VERSION ""

NS_ :

BS_:

BU_: EON PCM XXX EPS VSA

BO_ 356 HEADLIGHT_STATUS: 8 PCM
 SG_ LOW_BEAM_STATUS : 1|1@1+ (1,0) [0|1] "" Vector__XXX

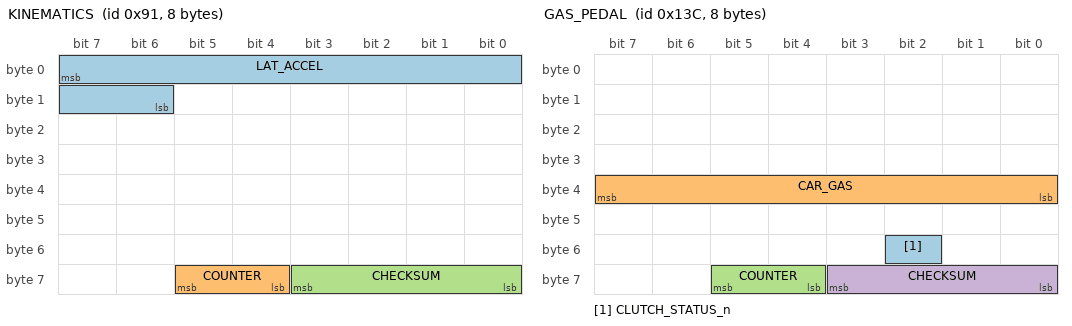
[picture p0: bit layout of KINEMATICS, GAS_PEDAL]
BO_ 145 KINEMATICS: 8 XXX
 SG_ LAT_ACCEL : 7|10@0+ (0.02,-512) [-20|20] "m/s2"  EON
 SG_ COUNTER : 61|2@0+ (1,0) [0|3] ""  EON
 SG_ CHECKSUM : 59|4@0+ (1,0) [0|3] ""  EON

BO_ 316 GAS_PEDAL: 8 PCM
 SG_ CLUTCH_STATUS_n : 50|1@0+ (1,0) [0|1] "" Vector__XXX
 SG_ CAR_GAS : 39|8@0+ (1,0) [0|255] ""  EON
 SG_ COUNTER : 61|2@0+ (1,0) [0|3] ""  EON
 SG_ CHECKSUM : 59|4@0+ (1,0) [0|15] ""  EON

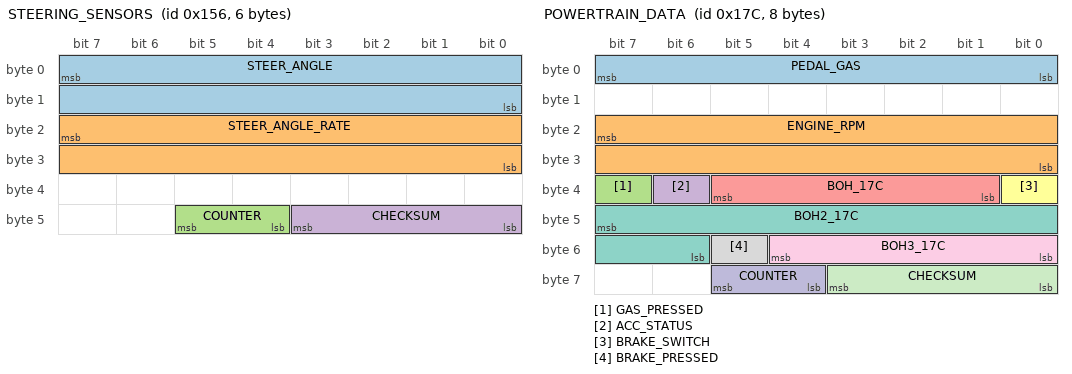
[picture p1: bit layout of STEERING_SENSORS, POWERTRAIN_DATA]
BO_ 342 STEERING_SENSORS: 6 EPS
 SG_ STEER_ANGLE : 7|16@0- (-0.1,0) [-500|500] "deg"  EON
 SG_ STEER_ANGLE_RATE : 23|16@0- (-1,0) [-3000|3000] "deg/s"  EON
 SG_ COUNTER : 45|2@0+ (1,0) [0|3] ""  EON
 SG_ CHECKSUM : 43|4@0+ (1,0) [0|15] ""  EON

BO_ 380 POWERTRAIN_DATA: 8 PCM
 SG_ PEDAL_GAS : 7|8@0+ (1,0) [0|255] ""  EON
 SG_ ENGINE_RPM : 23|16@0+ (1,0) [0|65535] ""  EON
 SG_ GAS_PRESSED : 39|1@0+ (1,0) [0|1] ""  EON
 SG_ ACC_STATUS : 38|1@0+ (1,0) [0|1] ""  EON
 SG_ BOH_17C : 37|5@0+ (1,0) [0|1] ""  EON
 SG_ BRAKE_SWITCH : 32|1@0+ (1,0) [0|1] ""  EON
 SG_ BOH2_17C : 47|10@0+ (1,0) [0|1] ""  EON
 SG_ BRAKE_PRESSED : 53|1@0+ (1,0) [0|1] ""  EON
 SG_ BOH3_17C : 52|5@0+ (1,0) [0|1] ""  EON
 SG_ COUNTER : 61|2@0+ (1,0) [0|3] ""  EON
 SG_ CHECKSUM : 59|4@0+ (1,0) [0|15] ""  EON

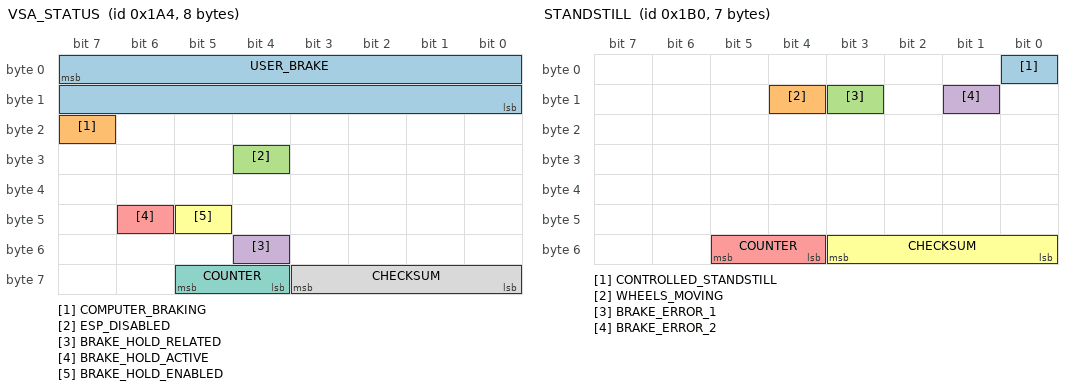
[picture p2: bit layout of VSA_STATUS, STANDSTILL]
BO_ 420 VSA_STATUS: 8 VSA
 SG_ USER_BRAKE : 7|16@0+ (0.015625,-1.609375) [0|1000] ""  EON
 SG_ COMPUTER_BRAKING : 23|1@0+ (1,0) [0|1] ""  EON
 SG_ ESP_DISABLED : 28|1@0+ (1,0) [0|1] ""  EON
 SG_ BRAKE_HOLD_RELATED : 52|1@0+ (1,0) [0|1] ""  XXX
 SG_ BRAKE_HOLD_ACTIVE : 46|1@0+ (1,0) [0|1] ""  EON
 SG_ BRAKE_HOLD_ENABLED : 45|1@0+ (1,0) [0|1] ""  EON
 SG_ COUNTER : 61|2@0+ (1,0) [0|3] ""  EON
 SG_ CHECKSUM : 59|4@0+ (1,0) [0|15] ""  EON

BO_ 432 STANDSTILL: 7 VSA
 SG_ CONTROLLED_STANDSTILL : 0|1@0+ (1,0) [0|1] ""  EON
 SG_ WHEELS_MOVING : 12|1@0+ (1,0) [0|1] ""  EON
 SG_ BRAKE_ERROR_1 : 11|1@0+ (1,0) [0|1] ""  EON
 SG_ BRAKE_ERROR_2 : 9|1@0+ (1,0) [0|1] ""  EON
 SG_ COUNTER : 53|2@0+ (1,0) [0|3] ""  EON
 SG_ CHECKSUM : 51|4@0+ (1,0) [0|3] ""  EON

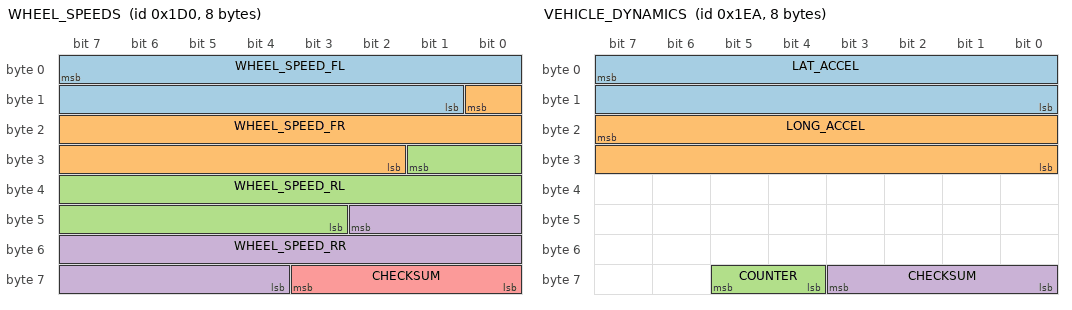
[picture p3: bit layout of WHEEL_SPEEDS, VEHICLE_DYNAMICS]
BO_ 464 WHEEL_SPEEDS: 8 VSA
 SG_ WHEEL_SPEED_FL : 7|15@0+ (0.01,0) [0|250] "kph"  EON
 SG_ WHEEL_SPEED_FR : 8|15@0+ (0.01,0) [0|250] "kph"  EON
 SG_ WHEEL_SPEED_RL : 25|15@0+ (0.01,0) [0|250] "kph"  EON
 SG_ WHEEL_SPEED_RR : 42|15@0+ (0.01,0) [0|250] "kph"  EON
 SG_ CHECKSUM : 59|4@0+ (1,0) [0|3] ""  EON

BO_ 490 VEHICLE_DYNAMICS: 8 VSA
 SG_ LAT_ACCEL : 7|16@0- (0.0015,0) [-20|20] "m/s2"  EON
 SG_ LONG_ACCEL : 23|16@0- (0.0015,0) [-20|20] "m/s2"  EON
 SG_ COUNTER : 61|2@0+ (1,0) [0|3] ""  EON
 SG_ CHECKSUM : 59|4@0+ (1,0) [0|3] ""  EON

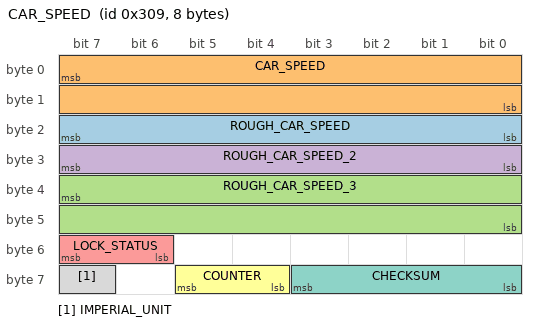
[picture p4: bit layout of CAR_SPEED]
BO_ 777 CAR_SPEED: 8 PCM
 SG_ ROUGH_CAR_SPEED : 23|8@0+ (1,0) [0|255] "mph"  XXX
 SG_ CAR_SPEED : 7|16@0+ (0.01,0) [0|65535] "kph"  XXX
 SG_ ROUGH_CAR_SPEED_3 : 39|16@0+ (0.01,0) [0|65535] "kph"  XXX
 SG_ ROUGH_CAR_SPEED_2 : 31|8@0+ (1,0) [0|255] "mph"  XXX
 SG_ LOCK_STATUS : 55|2@0+ (1,0) [0|255] ""  XXX
 SG_ COUNTER : 61|2@0+ (1,0) [0|3] ""  XXX
 SG_ CHECKSUM : 59|4@0+ (1,0) [0|15] ""  XXX
 SG_ IMPERIAL_UNIT : 63|1@0+ (1,0) [0|1] ""  XXX

BA_DEF_  "BusType" STRING ;
BA_DEF_DEF_  "BusType" "CAN";
